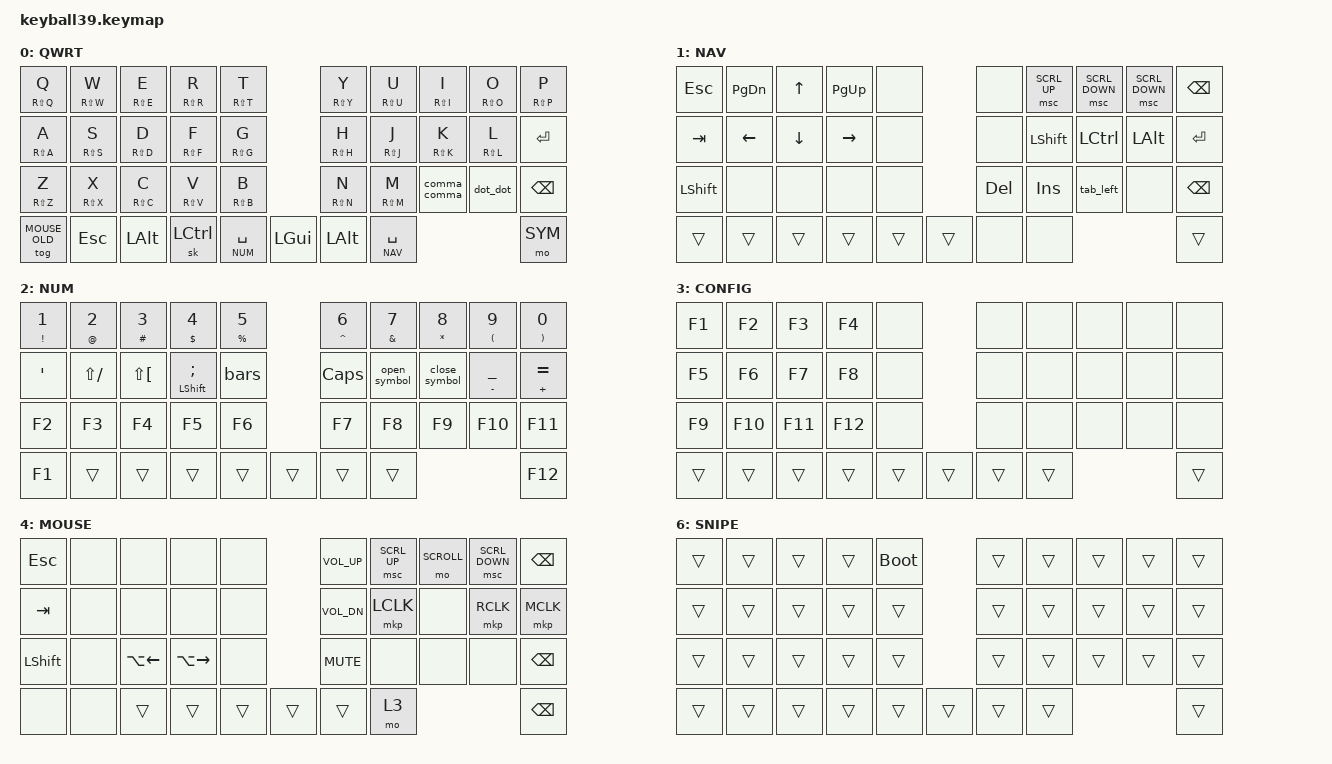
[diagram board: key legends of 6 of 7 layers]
#define DEFAULT 0
#define NUM     1
#define SYM     2
#define FUN     3
#define MOUSE_OLD   4
#define SCROLL  5
#define SNIPE   6

#include <behaviors/mouse_keys.dtsi>
#include <dt-bindings/zmk/mouse.h>
#include <behaviors.dtsi>
#include <dt-bindings/zmk/bt.h>
#include <dt-bindings/zmk/keys.h>

&lt {
    tapping-term-ms = <240>;
    flavor = "balanced";
    quick-tap-ms = <150>;
};

&mt {
    tapping-term-ms = <200>;
    flavor = "tap-preferred";
    quick-tap-ms = <150>;
};

&caps_word { continue-list = <UNDERSCORE MINUS>; };

/ {
    // custom shift using mod-morph 

    behaviors {
        cmqus: comma_question {
            compatible = "zmk,behavior-mod-morph";
            label = "COMMA_QUESTION";
            #binding-cells = <0>;
            bindings = <&kp COMMA>, <&kp QUESTION>;
            mods = <(MOD_LSFT|MOD_RSFT)>;
        };

        dtsmi: dot_semi {
            compatible = "zmk,behavior-mod-morph";
            label = "DOT_SEMI";
            #binding-cells = <0>;
            bindings = <&kp DOT>, <&kp SEMI>;
            mods = <(MOD_LSFT|MOD_RSFT)>;
        };

        // Volume control behavior
        vol_up: volume_up {
            compatible = "zmk,behavior-key-press";
            label = "VOLUME_UP";
            #binding-cells = <0>;
            bindings = <&kp C_VOL_UP>;
        };

        vol_dn: volume_down {
            compatible = "zmk,behavior-key-press";
            label = "VOLUME_DOWN";
            #binding-cells = <0>;
            bindings = <&kp C_VOL_DN>;
        };

        open_symbol: td_open {
            compatible = "zmk,behavior-tap-dance";
            label = "TD_OPEN";
            #binding-cells = <0>;
            tapping-term-ms = <200>;
            bindings = <&kp RS(RIGHT_BRACKET)>, <&kp RS(NUMBER_9)>, <&kp RIGHT_BRACKET>, <&kp LT>;
        };

        close_symbol: td_close {
            compatible = "zmk,behavior-tap-dance";
            label = "TD_CLOSE";
            #binding-cells = <0>;
            tapping-term-ms = <200>;
            bindings = <&kp RS(BACKSLASH)>, <&kp RS(NUMBER_0)>, <&kp BACKSLASH>, <&kp GT>;
        };

        dot_dot: dot_dot {
            compatible = "zmk,behavior-tap-dance";
            label = "DOT_DOT";
            #binding-cells = <0>;
            tapping-term-ms = <200>;
            bindings = <&kp PERIOD>, <&kp LS(SLASH)>;
        };

        comma_comma: comma_comma {
            compatible = "zmk,behavior-tap-dance";
            label = "COMMA_COMMA";
            #binding-cells = <0>;
            tapping-term-ms = <200>;
            bindings = <&kp COMMA>, <&kp SLASH>;
        };

        bars: bars {
            compatible = "zmk,behavior-tap-dance";
            label = "BARS";
            #binding-cells = <0>;
            tapping-term-ms = <200>;
            bindings = <&kp KP_SLASH>, <&kp LS(NON_US_BSLH)>, <&kp NON_US_BACKSLASH>;
        };

        // Conditional behavior for tab navigation
        tab_left: tab_left {
            compatible = "zmk,behavior-mod-morph";
            label = "TAB_LEFT";
            #binding-cells = <0>;
            bindings = <&kp LC(PAGE_UP)>, <&kp LG(LA(LEFT))>;
            mods = <(MOD_LGUI)>;
        };

        tab_right: tab_right {
            compatible = "zmk,behavior-mod-morph";
            label = "TAB_RIGHT";
            #binding-cells = <0>;
            bindings = <&kp LC(PAGE_DOWN)>, <&kp LG(LA(RIGHT))>;
            mods = <(MOD_LGUI)>;
        };
    };




    keymap {
        compatible = "zmk,keymap";

        default_layer {
            label = "QWRT";
            bindings = <
                &mt RS(Q) Q            &mt RS(W) W            &mt RS(E) E            &mt RS(R) R            &mt RS(T) T                                            &mt RS(Y) Y             &mt RS(U) U            &mt RS(I) I            &mt RS(O) O            &mt RS(P) P 
                &mt RS(A) A            &mt RS(S) S            &mt RS(D) D            &mt RS(F) F            &mt RS(G) G                                            &mt RS(H) H             &mt RS(J) J            &mt RS(K) K            &mt RS(L) L            &kp ENTER
                &mt RS(Z) Z            &mt RS(X) X            &mt RS(C) C            &mt RS(V) V            &mt RS(B) B                                            &mt RS(N) N             &mt RS(M) M            &comma_comma           &dot_dot               &kp BSPC          
                &tog MOUSE_OLD         &kp ESC                &kp LALT               &sk LEFT_CONTROL       &lt NUM SPACE      &kp LEFT_GUI                        &kp LALT                &lt NAV SPACE                                                 &mo SYM

            >;
        };

        navigation_layer {
            label = "NAV";
            bindings = <
                &kp ESC                &kp PAGE_DOWN          &kp UP                 &kp PAGE_UP            &none                                                   &none                  &msc SCRL_UP           &msc SCRL_DOWN         &msc SCRL_DOWN         &kp BSPC
                &kp TAB                &kp LEFT               &kp DOWN               &kp RIGHT              &none                                                   &none                  &kp LEFT_SHIFT         &kp LEFT_CONTROL       &kp LALT               &kp RETURN
                &kp LSHIFT             &none                  &none                  &none                  &none                                                   &kp DEL                &kp INSERT             &tab_left              &none                  &kp BSPC
                &trans                 &trans                 &trans                 &trans                 &trans             &trans                               &none                  &none                                                                &trans
             >;
        };
 

        number_layer {
            label = "NUM";
            bindings = <
            &mt EXCLAMATION NUMBER_1            &mt AT_SIGN NUMBER_2            &mt HASH NUMBER_3            &mt DOLLAR NUMBER_4                  &mt PERCENT NUMBER_5                              &mt CARET NUMBER_6                  &mt AMPERSAND NUMBER_7                  &mt ASTERISK NUMBER_8                  &mt LEFT_PARENTHESIS NUMBER_9                  &mt RIGHT_PARENTHESIS NUMBER_0
            &kp SINGLE_QUOTE                    &kp LS(SLASH)                   &kp LS(LEFT_BRACKET)         &mt LEFT_SHIFT SEMICOLON             &bars                                             &kp CAPS                            &open_symbol                            &close_symbol                          &mt MINUS UNDER                                &mt PLUS EQUAL  
            &kp F2                              &kp F3                          &kp F4                       &kp F5                               &kp F6                                            &kp F7                              &kp F8                                  &kp F9                                 &kp F10                                        &kp F11 
            &kp F1                              &trans                          &trans                       &trans                              &trans                                             &trans                              &trans                                  &trans                                                                                &kp F12
            >;
        };


         config_layer {
            label = "CONFIG";
            bindings = <
                &kp F1  &kp F2   &kp F3   &kp F4   &none                   &none   &none  &none  &none  &none
                &kp F5  &kp F6   &kp F7   &kp F8   &none                   &none   &none  &none  &none  &none
                &kp F9  &kp F10  &kp F11  &kp F12  &none                   &none   &none  &none  &none  &none
                &trans  &trans   &trans   &trans   &trans  &trans  &trans  &trans                       &trans
            >;
        };

        mouse_layer {
            label = "MOUSE";
            bindings = <
                &kp ESC               &none              &none             &none          &none                           &kp C_VOL_UP            &msc SCRL_UP   &mo SCROLL         &msc SCRL_DOWN         &kp BSPC
                &kp TAB               &none              &none             &none          &none                           &kp C_VOL_DN            &mkp LCLK      &none              &mkp RCLK              &mkp MCLK
                &kp LSHIFT            &none              &kp LA(LEFT)      &kp LA(RIGHT)  &none                           &kp C_MUTE              &none          &none              &none                  &kp BSPC
                &none                 &none              &trans            &trans         &trans      &trans              &trans  &mo 3                                                                    &kp BSPC
            >;
        };

        scroll_layer {
            label = "SCROLL";
            bindings = <
                &kp C_VOL_UP        &kp C_VOL_DN        &kp C_MUTE         &kp C_PREV         &kp C_NEXT                                             &kp C_VOL_UP            &kp C_VOL_DN         &kp C_MUTE            &kp C_PREV            &kp C_NEXT
                &kp C_VOL_UP        &kp C_VOL_DN        &kp C_MUTE         &kp C_PREV         &kp C_NEXT                                             &kp C_VOL_UP            &kp C_VOL_DN         &kp C_MUTE            &kp C_PREV            &kp C_NEXT
                &kp C_VOL_UP        &kp C_VOL_DN        &kp C_MUTE         &kp C_PREV         &kp C_NEXT                                             &kp C_VOL_UP            &kp C_VOL_DN         &kp C_MUTE            &kp C_PREV            &kp C_NEXT
                &kp C_VOL_UP        &kp C_VOL_DN        &kp C_MUTE         &kp C_PREV         &kp C_NEXT  &kp C_NEXT  &kp C_PREV  &kp C_MUTE                            &kp C_VOL_DN                                                                        &kp C_VOL_UP
            >;
        };

        snipe_layer {
            label = "SNIPE";
            bindings = <
&trans  &trans  &trans  &trans  &bootloader                  &trans  &trans  &trans  &trans  &trans
&trans  &trans  &trans  &trans  &trans                       &trans  &trans  &trans  &trans  &trans
&trans  &trans  &trans  &trans  &trans                       &trans  &trans  &trans  &trans  &trans
&trans  &trans  &trans  &trans  &trans       &trans  &trans  &trans                          &trans
            >;
        };
    };
};
